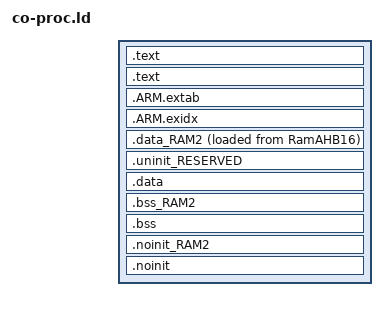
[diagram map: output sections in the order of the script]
INCLUDE "co-proc_memory.ld"

ENTRY(ResetISR)

SECTIONS
{
    /* MAIN TEXT SECTION */
    .text : ALIGN(4)
    {
        FILL(0xff)
        __vectors_start__ = ABSOLUTE(.) ;
        KEEP(*(.isr_vector))
        /* Global Section Table */
        . = ALIGN(4) ; 
        __section_table_start = .;
        __data_section_table = .;
        LONG(LOADADDR(.data));
        LONG(    ADDR(.data));
        LONG(  SIZEOF(.data));
        LONG(LOADADDR(.data_RAM2));
        LONG(    ADDR(.data_RAM2));
        LONG(  SIZEOF(.data_RAM2));
        __data_section_table_end = .;
        __bss_section_table = .;
        LONG(    ADDR(.bss));
        LONG(  SIZEOF(.bss));
        LONG(    ADDR(.bss_RAM2));
        LONG(  SIZEOF(.bss_RAM2));
        __bss_section_table_end = .;
        __section_table_end = . ;
	    /* End of Global Section Table */

        *(.after_vectors*)

    } >RamAHB16

    .text : ALIGN(4)    
    {
        *(.text*)
        *(.rodata .rodata.* .constdata .constdata.*)
        . = ALIGN(4);
    } > RamAHB16
    /*
     * for exception handling/unwind - some Newlib functions (in common
     * with C++ and STDC++) use this. 
     */
    .ARM.extab : ALIGN(4) 
    {
        *(.ARM.extab* .gnu.linkonce.armextab.*)
    } > RamAHB16
    __exidx_start = .;

    .ARM.exidx : ALIGN(4)
    {
        *(.ARM.exidx* .gnu.linkonce.armexidx.*)
    } > RamAHB16
    __exidx_end = .;

    _etext = .;
        
    /* DATA section for RamAHB_ETB16 */
    .data_RAM2 : ALIGN(4)
    {
        FILL(0xff)
        PROVIDE(__start_data_RAM2 = .) ;
        *(.ramfunc.$RAM2)
        *(.ramfunc.$RamAHB_ETB16)
        *(.data.$RAM2*)
        *(.data.$RamAHB_ETB16*)
        . = ALIGN(4) ;
        PROVIDE(__end_data_RAM2 = .) ;
     } > RamAHB_ETB16 AT>RamAHB16

    /* MAIN DATA SECTION */
    .uninit_RESERVED : ALIGN(4)
    {
        KEEP(*(.bss.$RESERVED*))
        . = ALIGN(4) ;
        _end_uninit_RESERVED = .;
    } > RamAHB16
    /* Main DATA section (RamAHB16) */
    .data : ALIGN(4)
    {
       FILL(0xff)
       _data = . ;
       *(vtable)
       *(.ramfunc*)
       *(.data*)
       . = ALIGN(4) ;
       _edata = . ;
    } > RamAHB16 AT>RamAHB16
    /* BSS section for RamAHB_ETB16 */
    .bss_RAM2 : ALIGN(4)
    {
       PROVIDE(__start_bss_RAM2 = .) ;
       *(.bss.$RAM2*)
       *(.bss.$RamAHB_ETB16*)
       . = ALIGN (. != 0 ? 4 : 1) ; /* avoid empty segment */
       PROVIDE(__end_bss_RAM2 = .) ;
    } > RamAHB_ETB16 
    /* MAIN BSS SECTION */
    .bss : ALIGN(4)
    {
        _bss = .;
        *(.bss*)
        *(COMMON)
        . = ALIGN(4) ;
        _ebss = .;
        PROVIDE(end = .);
    } > RamAHB16
    /* NOINIT section for RamAHB_ETB16 */
    .noinit_RAM2 (NOLOAD) : ALIGN(4)
    {
       *(.noinit.$RAM2*)
       *(.noinit.$RamAHB_ETB16*)
       . = ALIGN(4) ;
    } > RamAHB_ETB16 
    /* DEFAULT NOINIT SECTION */
    .noinit (NOLOAD): ALIGN(4)
    {
        _noinit = .;
        *(.noinit*) 
         . = ALIGN(4) ;
        _end_noinit = .;
    } > RamAHB16

    PROVIDE(_pvHeapStart = DEFINED(__user_heap_base) ? __user_heap_base : .);
    PROVIDE(_vStackTop = DEFINED(__user_stack_top) ? __user_stack_top : __top_RamAHB16 - 0);
}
